# ioam3358 register map
Registers are 32-bit, access not given, no defined reset value unless marked. A register's access mark holds for its fields unless they carry their own. Addresses are absolute; registers are grouped by the start of their names; [hi:lo] are bit positions; {n}, {i} and the like mark numbered series; 'fields as' and 'values as' point back to an identical list.

## McASP1
0x46400000 McASP1_RBUF
0x46400000 McASP1_XBUF
0x4803C000 McASP1_REV
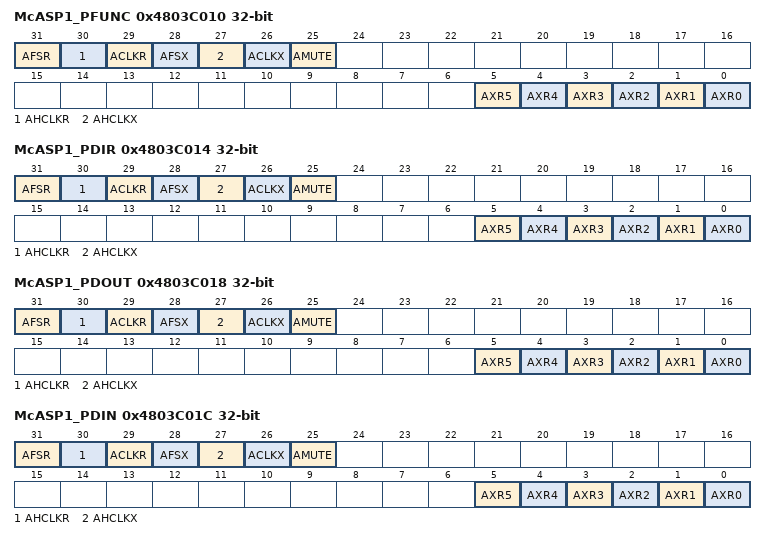
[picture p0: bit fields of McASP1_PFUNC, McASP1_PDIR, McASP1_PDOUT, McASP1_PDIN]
0x4803C010 McASP1_PFUNC
  [31] AFSR, [30] AHCLKR, [29] ACLKR, [28] AFSX, [27] AHCLKX, [26] ACLKX, [25] AMUTE, [n] AXR{n} (n=0..5)
0x4803C014 McASP1_PDIR
  fields as McASP1_PFUNC
0x4803C018 McASP1_PDOUT
  fields as McASP1_PFUNC
0x4803C01C McASP1_PDIN
  fields as McASP1_PFUNC
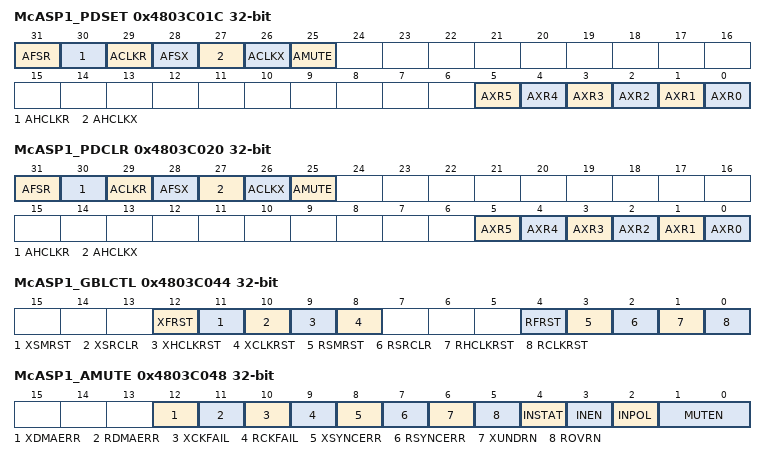
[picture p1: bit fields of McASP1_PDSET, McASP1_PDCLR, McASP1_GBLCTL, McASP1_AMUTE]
0x4803C01C McASP1_PDSET
  fields as McASP1_PFUNC
0x4803C020 McASP1_PDCLR
  fields as McASP1_PFUNC
0x4803C044 McASP1_GBLCTL
  [12] XFRST, [11] XSMRST, [10] XSRCLR, [9] XHCLKRST, [8] XCLKRST, [4] RFRST, [3] RSMRST, [2] RSRCLR, [1] RHCLKRST, [0] RCLKRST
0x4803C048 McASP1_AMUTE
  [12] XDMAERR, [11] RDMAERR, [10] XCKFAIL, [9] RCKFAIL, [8] XSYNCERR, [7] RSYNCERR, [6] XUNDRN, [5] ROVRN, [4] INSTAT, [3] INEN, [2] INPOL, [1:0] MUTEN
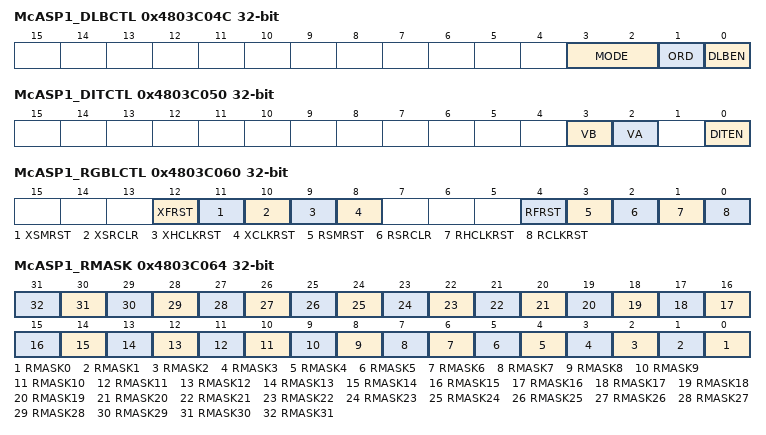
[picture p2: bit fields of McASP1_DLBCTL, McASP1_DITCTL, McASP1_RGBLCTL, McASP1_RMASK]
0x4803C04C McASP1_DLBCTL
  [3:2] MODE, [1] ORD, [0] DLBEN
0x4803C050 McASP1_DITCTL
  [3] VB, [2] VA, [0] DITEN
0x4803C060 McASP1_RGBLCTL
  fields as McASP1_GBLCTL
0x4803C064 McASP1_RMASK
  [n] RMASK{n} (n=0..31)
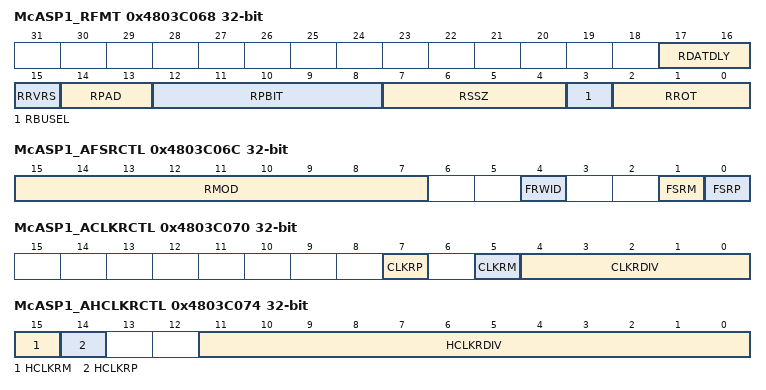
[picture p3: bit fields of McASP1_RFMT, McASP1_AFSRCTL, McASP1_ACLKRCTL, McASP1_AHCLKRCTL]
0x4803C068 McASP1_RFMT
  [17:16] RDATDLY, [15] RRVRS, [14:13] RPAD, [12:8] RPBIT, [7:4] RSSZ, [3] RBUSEL, [2:0] RROT
0x4803C06C McASP1_AFSRCTL
  [15:7] RMOD, [4] FRWID, [1] FSRM, [0] FSRP
0x4803C070 McASP1_ACLKRCTL
  [7] CLKRP, [5] CLKRM, [4:0] CLKRDIV
0x4803C074 McASP1_AHCLKRCTL
  [15] HCLKRM, [14] HCLKRP, [11:0] HCLKRDIV
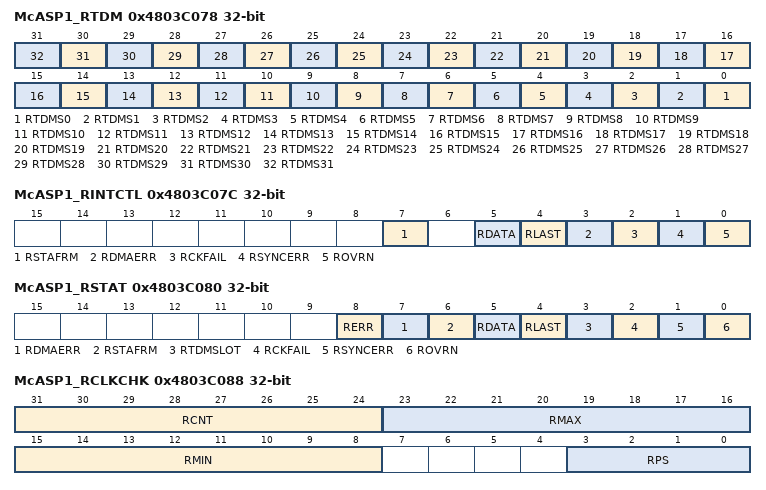
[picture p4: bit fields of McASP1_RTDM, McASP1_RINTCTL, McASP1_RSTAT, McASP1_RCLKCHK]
0x4803C078 McASP1_RTDM
  [n] RTDMS{n} (n=0..31)
0x4803C07C McASP1_RINTCTL
  [7] RSTAFRM, [5] RDATA, [4] RLAST, [3] RDMAERR, [2] RCKFAIL, [1] RSYNCERR, [0] ROVRN
0x4803C080 McASP1_RSTAT
  [8] RERR, [7] RDMAERR, [6] RSTAFRM, [5] RDATA, [4] RLAST, [3] RTDMSLOT, [2] RCKFAIL, [1] RSYNCERR, [0] ROVRN
0x4803C084 McASP1_RSLOT
  [8:0] RSLOTCNT
0x4803C088 McASP1_RCLKCHK
  [31:24] RCNT, [23:16] RMAX, [15:8] RMIN, [3:0] RPS
0x4803C08C McASP1_REVTCTL
  [0] RDATDMA
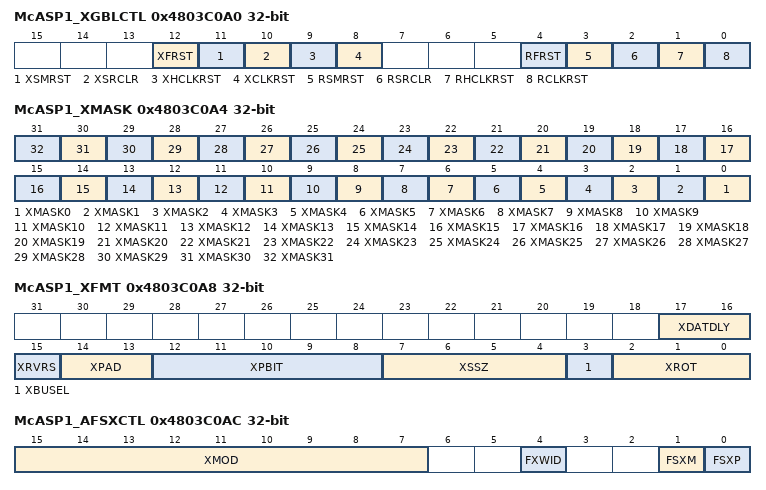
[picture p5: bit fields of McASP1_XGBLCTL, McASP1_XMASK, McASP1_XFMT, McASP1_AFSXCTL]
0x4803C0A0 McASP1_XGBLCTL
  fields as McASP1_GBLCTL
0x4803C0A4 McASP1_XMASK
  [n] XMASK{n} (n=0..31)
0x4803C0A8 McASP1_XFMT
  [17:16] XDATDLY, [15] XRVRS, [14:13] XPAD, [12:8] XPBIT, [7:4] XSSZ, [3] XBUSEL, [2:0] XROT
0x4803C0AC McASP1_AFSXCTL
  [15:7] XMOD, [4] FXWID, [1] FSXM, [0] FSXP
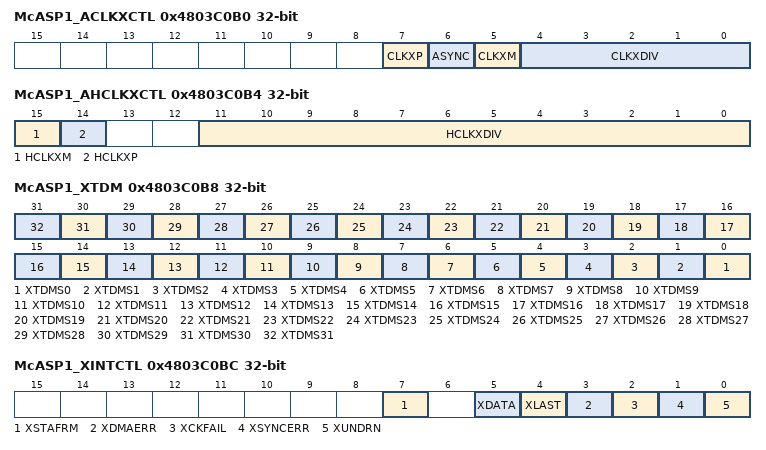
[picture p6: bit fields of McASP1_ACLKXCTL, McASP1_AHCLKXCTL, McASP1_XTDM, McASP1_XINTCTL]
0x4803C0B0 McASP1_ACLKXCTL
  [7] CLKXP, [6] ASYNC, [5] CLKXM, [4:0] CLKXDIV
0x4803C0B4 McASP1_AHCLKXCTL
  [15] HCLKXM, [14] HCLKXP, [11:0] HCLKXDIV
0x4803C0B8 McASP1_XTDM
  [n] XTDMS{n} (n=0..31)
0x4803C0BC McASP1_XINTCTL
  [7] XSTAFRM, [5] XDATA, [4] XLAST, [3] XDMAERR, [2] XCKFAIL, [1] XSYNCERR, [0] XUNDRN
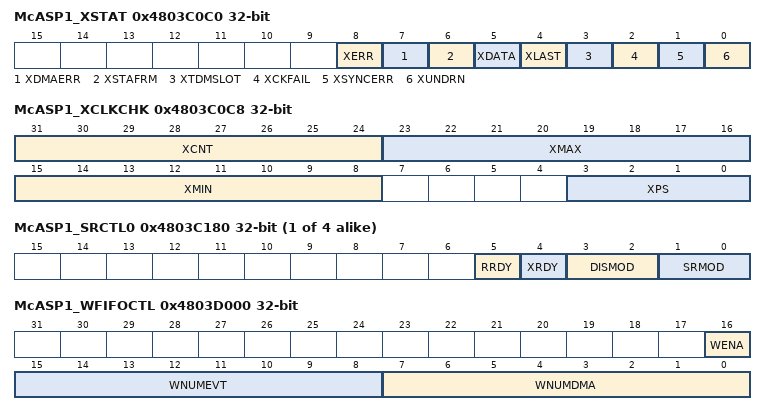
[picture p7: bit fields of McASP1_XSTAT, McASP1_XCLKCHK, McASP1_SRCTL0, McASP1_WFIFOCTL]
0x4803C0C0 McASP1_XSTAT
  [8] XERR, [7] XDMAERR, [6] XSTAFRM, [5] XDATA, [4] XLAST, [3] XTDMSLOT, [2] XCKFAIL, [1] XSYNCERR, [0] XUNDRN
0x4803C0C4 McASP1_XSLOT
  [9:0] XSLOTCNT
0x4803C0C8 McASP1_XCLKCHK
  [31:24] XCNT, [23:16] XMAX, [15:8] XMIN, [3:0] XPS
0x4803C0CC McASP1_XEVTCTL
  [0] XDATDMA
{0x4803C100+4i} McASP1_DITCSRA{i} (i=0..5)
{0x4803C118+4i} McASP1_DITCSRB{i} (i=0..5)
{0x4803C130+4i} McASP1_DITUDRA{i} (i=0..5)
{0x4803C148+4i} McASP1_DITUDRB{i} (i=0..5)
{0x4803C180+4i} McASP1_SRCTL{i} (i=0..3)
  [5] RRDY, [4] XRDY, [3:2] DISMOD, [1:0] SRMOD
{0x4803C200+4i} McASP1_XBUF{i} (i=0..3)
{0x4803C280+4i} McASP1_RBUF{i} (i=0..3)
0x4803D000 McASP1_WFIFOCTL
  [16] WENA, [15:8] WNUMEVT, [7:0] WNUMDMA
0x4803D004 McASP1_WFIFOSTS
  [7:0] WLVL
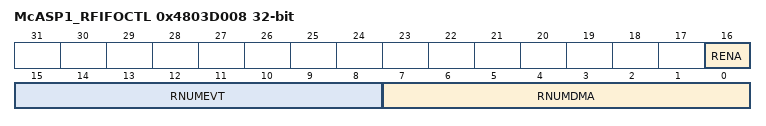
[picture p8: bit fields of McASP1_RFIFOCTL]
0x4803D008 McASP1_RFIFOCTL
  [16] RENA, [15:8] RNUMEVT, [7:0] RNUMDMA
0x4803D00C McASP1_RFIFOSTS
  [7:0] RLVL

## MCSPI0
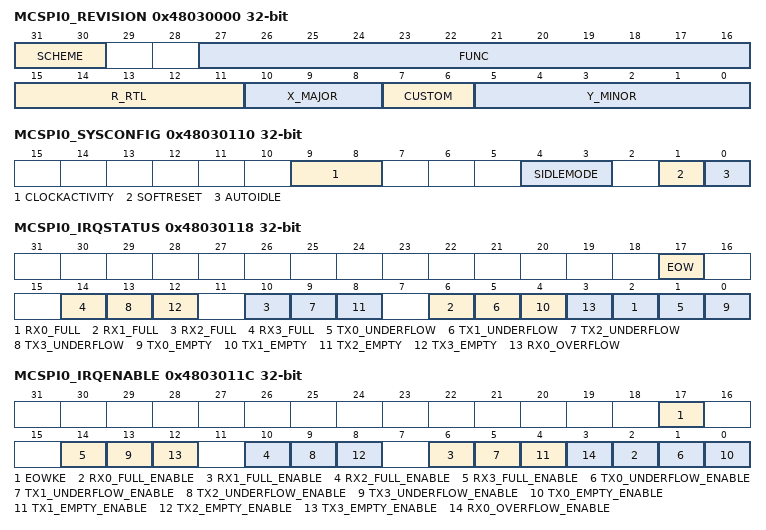
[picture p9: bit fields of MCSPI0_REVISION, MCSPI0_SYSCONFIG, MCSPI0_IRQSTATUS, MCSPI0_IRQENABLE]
0x48030000 MCSPI0_REVISION
  [31:30] SCHEME, [27:16] FUNC, [15:11] R_RTL, [10:8] X_MAJOR, [7:6] CUSTOM, [5:0] Y_MINOR
0x48030110 MCSPI0_SYSCONFIG
  [9:8] CLOCKACTIVITY, [4:3] SIDLEMODE, [1] SOFTRESET, [0] AUTOIDLE
0x48030114 MCSPI0_SYSSTATUS
  [0] RESETDONE
0x48030118 MCSPI0_IRQSTATUS
  [17] EOW, [4n+2] RX{n}_FULL (n=0..3), [4n+1] TX{n}_UNDERFLOW (n=0..3), [4n] TX{n}_EMPTY (n=0..3), [3] RX0_OVERFLOW
0x4803011C MCSPI0_IRQENABLE
  [17] EOWKE, [4n+2] RX{n}_FULL_ENABLE (n=0..3), [4n+1] TX{n}_UNDERFLOW_ENABLE (n=0..3), [4n] TX{n}_EMPTY_ENABLE (n=0..3), [3] RX0_OVERFLOW_ENABLE
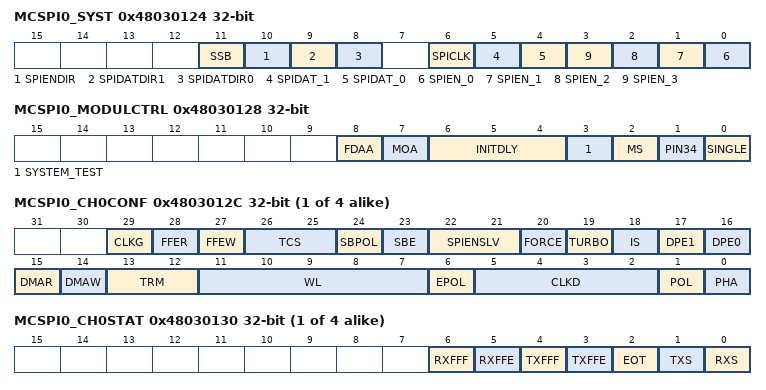
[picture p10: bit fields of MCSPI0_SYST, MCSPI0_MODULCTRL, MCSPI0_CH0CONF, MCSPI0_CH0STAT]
0x48030124 MCSPI0_SYST
  [11] SSB, [10] SPIENDIR, [9] SPIDATDIR1, [8] SPIDATDIR0, [6] SPICLK, [5] SPIDAT_1, [4] SPIDAT_0, [n] SPIEN_{n} (n=0..3)
0x48030128 MCSPI0_MODULCTRL
  [8] FDAA, [7] MOA, [6:4] INITDLY, [3] SYSTEM_TEST, [2] MS, [1] PIN34, [0] SINGLE
{0x4803012C+0x14*i} MCSPI0_CH{i}CONF (i=0..3)
  [29] CLKG, [28] FFER, [27] FFEW, [26:25] TCS, [24] SBPOL, [23] SBE, [22:21] SPIENSLV, [20] FORCE, [19] TURBO, [18] IS, [17] DPE1, [16] DPE0, [15] DMAR, [14] DMAW, [13:12] TRM, [11:7] WL, [6] EPOL, [5:2] CLKD, [1] POL, [0] PHA
{0x48030130+0x14*i} MCSPI0_CH{i}STAT (i=0..3)
  [6] RXFFF, [5] RXFFE, [4] TXFFF, [3] TXFFE, [2] EOT, [1] TXS, [0] RXS
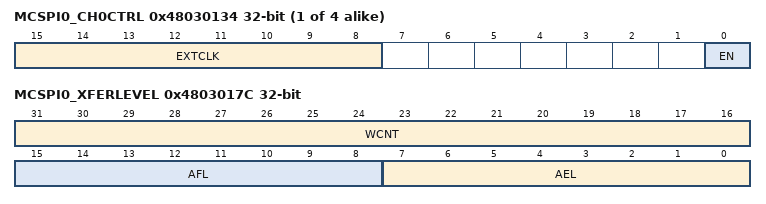
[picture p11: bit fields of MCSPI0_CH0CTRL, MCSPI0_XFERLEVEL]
{0x48030134+0x14*i} MCSPI0_CH{i}CTRL (i=0..3)
  [15:8] EXTCLK, [0] EN
{0x48030138+0x14*i} MCSPI0_TX{i} (i=0..3)
{0x4803013C+0x14*i} MCSPI0_RX{i} (i=0..3)
0x4803017C MCSPI0_XFERLEVEL
  [31:16] WCNT, [15:8] AFL, [7:0] AEL
0x48030180 MCSPI0_DAFTX
0x48030184 MCSPI0_DAFRX
